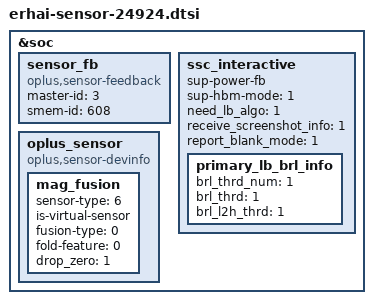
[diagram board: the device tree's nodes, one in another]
/**********************************************************************************
 * Copyright (c)  2022-2024  Guangdong oplus Mobile Comm Corp., Ltd
 * Description: oplus sensor dtsi
 *
 * Version: 1.0
 * Date: 2022-07-04
 *
 * ------------------------------ Revision History: --------------------------------
 * <version>         <date>        <author>                <desc>
 ***********************************************************************************/
#include <dt-bindings/regulator/qcom,rpmh-regulator-levels.h>

&soc {
    //#ifdef OPLUS_FEATURE_SENSOR_SMEM
    sensor_fb: sensor_fb {
        compatible = "oplus,sensor-feedback";
        master-id  = <3>;
        smem-id    = <608>;
    };
    ssc_interactive {
        sup-power-fb;
        sup-hbm-mode = <1>;
        need_lb_algo = <1>;
        receive_screenshot_info = <1>;
        report_blank_mode = <1>;

        primary_lb_brl_info {
            brl_thrd_num = <1>;
            brl_thrd = <1>;
            brl_l2h_thrd = <1>;
        };
    };
    oplus_sensor {
        compatible = "oplus,sensor-devinfo";
        /*virtual sensor*/
        mag_fusion {
            sensor-type = <6>;//OPLUS_MAG_FUSION
            is-virtual-sensor;
            fusion-type = <0>;//OPLUS_FUSION
            fold-feature = <0>;
            drop_zero = <1>;
        };
    };
    //#endif /*OPLUS_FEATURE_SENSOR_SMEM*/
};
